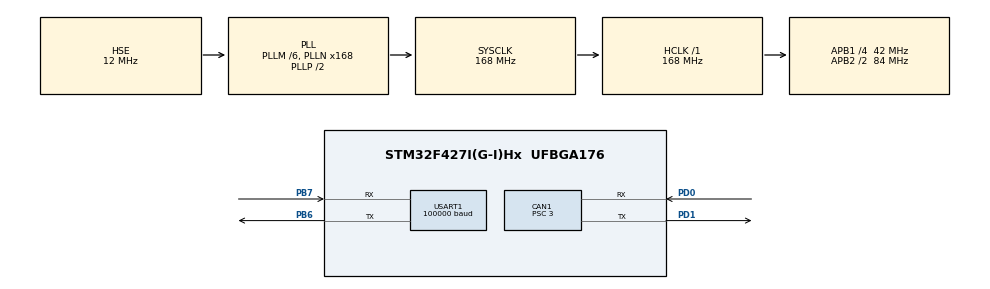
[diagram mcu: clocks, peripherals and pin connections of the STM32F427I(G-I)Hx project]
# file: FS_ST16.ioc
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CAN1.BS1=CAN_BS1_10TQ
CAN1.BS2=CAN_BS2_3TQ
CAN1.CalculateBaudRate=1000000
CAN1.CalculateTimeBit=1000
CAN1.CalculateTimeQuantum=71.42857142857143
CAN1.Prescaler=3
Dma.Request0=USART1_RX
Dma.USART1_RX.0.Direction=DMA_PERIPH_TO_MEMORY
Dma.USART1_RX.0.FIFOMode=DMA_FIFOMODE_DISABLE
Dma.USART1_RX.0.Instance=DMA2_Stream2
Dma.USART1_RX.0.MemDataAlignment=DMA_MDATAALIGN_BYTE
Dma.USART1_RX.0.MemInc=DMA_MINC_ENABLE
Dma.USART1_RX.0.Mode=DMA_CIRCULAR
Dma.USART1_RX.0.PeriphDataAlignment=DMA_PDATAALIGN_BYTE
Dma.USART1_RX.0.PeriphInc=DMA_PINC_DISABLE
Dma.USART1_RX.0.Priority=DMA_PRIORITY_LOW
FREERTOS.Tasks01=defaultTask,24,128,StartDefaultTask,Default,NULL,Dynamic,NULL,NULL
Mcu.Family=STM32F4
Mcu.Name=STM32F427I(G-I)Hx
Mcu.Package=UFBGA176
NVIC.CAN1_RX0_IRQn=true\:5\:0\:false\:false\:true\:true\:true\:true\:true
NVIC.DMA2_Stream2_IRQn=true\:5\:0\:false\:false\:true\:true\:false\:true\:true
NVIC.PriorityGroup=NVIC_PRIORITYGROUP_4
NVIC.TIM6_DAC_IRQn=true\:15\:0\:false\:false\:true\:false\:false\:true\:true
NVIC.TimeBase=TIM6_DAC_IRQn
NVIC.TimeBaseIP=TIM6
NVIC.USART1_IRQn=true\:5\:0\:false\:false\:true\:true\:true\:true\:true
PA13.Mode=Serial_Wire
PA13.Signal=SYS_JTMS-SWDIO
PA14.Mode=Serial_Wire
PA14.Signal=SYS_JTCK-SWCLK
PB6.Mode=Asynchronous
PB6.Signal=USART1_TX
PB7.Mode=Asynchronous
PB7.Signal=USART1_RX
PD0.Mode=CAN_Activate
PD0.Signal=CAN1_RX
PD1.Mode=CAN_Activate
PD1.Signal=CAN1_TX
PH0/OSC_IN.Mode=HSE-External-Oscillator
PH0/OSC_IN.Signal=RCC_OSC_IN
PH1/OSC_OUT.Mode=HSE-External-Oscillator
PH1/OSC_OUT.Signal=RCC_OSC_OUT
ProjectManager.HeapSize=0x200
ProjectManager.StackSize=0x400
ProjectManager.TargetToolchain=MDK-ARM V5.32
RCC.48MHZClocksFreq_Value=84000000
RCC.AHBFreq_Value=168000000
RCC.APB1CLKDivider=RCC_HCLK_DIV4
RCC.APB1Freq_Value=42000000
RCC.APB1TimFreq_Value=84000000
RCC.APB2CLKDivider=RCC_HCLK_DIV2
RCC.APB2Freq_Value=84000000
RCC.APB2TimFreq_Value=168000000
RCC.CortexFreq_Value=168000000
RCC.HCLKFreq_Value=168000000
RCC.HSE_VALUE=12000000
RCC.HSI_VALUE=16000000
RCC.LSE_VALUE=32768
RCC.PLLM=6
RCC.PLLN=168
RCC.PLLSourceVirtual=RCC_PLLSOURCE_HSE
RCC.SYSCLKFreq_VALUE=168000000
RCC.SYSCLKSource=RCC_SYSCLKSOURCE_PLLCLK
RCC.VCOOutputFreq_Value=336000000
TIM3.Prescaler=8299
USART1.BaudRate=100000
USART1.Mode=MODE_RX
USART1.Parity=PARITY_EVEN
USART1.StopBits=STOPBITS_2
USART1.VirtualMode=VM_ASYNC
USART1.WordLength=WORDLENGTH_8B
VP_FREERTOS_VS_CMSIS_V2.Mode=CMSIS_V2
VP_SYS_VS_tim6.Mode=TIM6
VP_TIM3_VS_ClockSourceINT.Mode=Internal
board=custom

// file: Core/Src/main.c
/* USER CODE BEGIN Header */
/**
 ******************************************************************************
 * @file           : main.c
 * @brief          : Main program body
 ******************************************************************************
 * @attention
 *
 * Copyright (c) 2026 STMicroelectronics.
 * All rights reserved.
 *
 * This software is licensed under terms that can be found in the LICENSE file
 * in the root directory of this software component.
 * If no LICENSE file comes with this software, it is provided AS-IS.
 *
 ******************************************************************************
 */
/* USER CODE END Header */
#include "main.h"
#include "cmsis_os.h"
#include "can.h"
#include "dma.h"
#include "tim.h"
#include "usart.h"
#include "gpio.h"

void SystemClock_Config(void);
void MX_FREERTOS_Init(void);

int main(void)
{

  /* MCU Configuration--------------------------------------------------------*/

  /* Reset of all peripherals, Initializes the Flash interface and the Systick. */
  HAL_Init();

  /* Configure the system clock */
  SystemClock_Config();

  /* Initialize all configured peripherals */
  MX_GPIO_Init();
  MX_DMA_Init();
  MX_CAN1_Init();
  MX_USART1_UART_Init();
  MX_TIM3_Init();

  /* Init scheduler */
  osKernelInitialize();  /* Call init function for freertos objects (in cmsis_os2.c) */
  MX_FREERTOS_Init();

  /* Start scheduler */
  osKernelStart();

  /* We should never get here as control is now taken by the scheduler */

  /* Infinite loop */
  while (1)
  {

  }
}

void SystemClock_Config(void)
{
  RCC_OscInitTypeDef RCC_OscInitStruct = {0};
  RCC_ClkInitTypeDef RCC_ClkInitStruct = {0};

  /** Configure the main internal regulator output voltage
  */
  __HAL_RCC_PWR_CLK_ENABLE();
  __HAL_PWR_VOLTAGESCALING_CONFIG(PWR_REGULATOR_VOLTAGE_SCALE1);

  /** Initializes the RCC Oscillators according to the specified parameters
  * in the RCC_OscInitTypeDef structure.
  */
  RCC_OscInitStruct.OscillatorType = RCC_OSCILLATORTYPE_HSE;
  RCC_OscInitStruct.HSEState = RCC_HSE_ON;
  RCC_OscInitStruct.PLL.PLLState = RCC_PLL_ON;
  RCC_OscInitStruct.PLL.PLLSource = RCC_PLLSOURCE_HSE;
  RCC_OscInitStruct.PLL.PLLM = 6;
  RCC_OscInitStruct.PLL.PLLN = 168;
  RCC_OscInitStruct.PLL.PLLP = RCC_PLLP_DIV2;
  RCC_OscInitStruct.PLL.PLLQ = 4;
  if (HAL_RCC_OscConfig(&RCC_OscInitStruct) != HAL_OK)
  {
    Error_Handler();
  }

  /** Initializes the CPU, AHB and APB buses clocks
  */
  RCC_ClkInitStruct.ClockType = RCC_CLOCKTYPE_HCLK|RCC_CLOCKTYPE_SYSCLK
                              |RCC_CLOCKTYPE_PCLK1|RCC_CLOCKTYPE_PCLK2;
  RCC_ClkInitStruct.SYSCLKSource = RCC_SYSCLKSOURCE_PLLCLK;
  RCC_ClkInitStruct.AHBCLKDivider = RCC_SYSCLK_DIV1;
  RCC_ClkInitStruct.APB1CLKDivider = RCC_HCLK_DIV4;
  RCC_ClkInitStruct.APB2CLKDivider = RCC_HCLK_DIV2;

  if (HAL_RCC_ClockConfig(&RCC_ClkInitStruct, FLASH_LATENCY_5) != HAL_OK)
  {
    Error_Handler();
  }
}

void HAL_TIM_PeriodElapsedCallback(TIM_HandleTypeDef *htim)
{
  if (htim->Instance == TIM6)
  {
    HAL_IncTick();
  }
  /* USER CODE BEGIN Callback 1 */
  if (htim == &htim3)
  {

  }
  /* USER CODE END Callback 1 */
}

void Error_Handler(void)
{
  __disable_irq();
  while (1)
  {
  }
}

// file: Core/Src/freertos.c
/* USER CODE BEGIN Header */
/**
 ******************************************************************************
 * File Name          : freertos.c
 * Description        : Code for freertos applications
 ******************************************************************************
 * @attention
 *
 * Copyright (c) 2026 STMicroelectronics.
 * All rights reserved.
 *
 * This software is licensed under terms that can be found in the LICENSE file
 * in the root directory of this software component.
 * If no LICENSE file comes with this software, it is provided AS-IS.
 *
 ******************************************************************************
 */
/* USER CODE END Header */

#include "FreeRTOS.h"
#include "task.h"
#include "main.h"
#include "cmsis_os.h"

/* Definitions for defaultTask */
osThreadId_t defaultTaskHandle;
const osThreadAttr_t defaultTask_attributes = {
  .name = "defaultTask",
  .stack_size = 128 * 4,
  .priority = (osPriority_t) osPriorityNormal,
};

/* USER CODE BEGIN FunctionPrototypes */
osThreadId_t rc_taskHandle;
const osThreadAttr_t rc_task_attributes = {
    .name = "rc_task",
    .stack_size = 128 * 4,
    .priority = (osPriority_t)osPriorityNormal1,
};
extern void rc_task(void *argument);
/* USER CODE END FunctionPrototypes */

void StartDefaultTask(void *argument);

void MX_FREERTOS_Init(void); /* (MISRA C 2004 rule 8.1) */

void MX_FREERTOS_Init(void) {

  /* Create the thread(s) */
  /* creation of defaultTask */
  defaultTaskHandle = osThreadNew(StartDefaultTask, NULL, &defaultTask_attributes);

  /* USER CODE BEGIN RTOS_THREADS */
  rc_taskHandle = osThreadNew(rc_task, NULL, &rc_task_attributes);
  /* add threads, ... */
  /* USER CODE END RTOS_THREADS */

}

void StartDefaultTask(void *argument)
{
  for (;;)
  {
    osDelay(1);
  }
}
